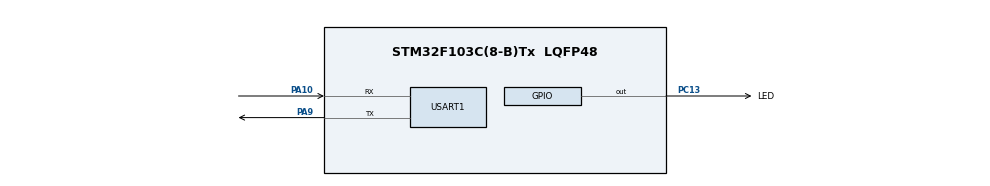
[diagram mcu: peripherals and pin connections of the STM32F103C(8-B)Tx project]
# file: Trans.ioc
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Dma.Request0=USART1_RX
Dma.Request1=USART1_TX
Dma.USART1_RX.0.Direction=DMA_PERIPH_TO_MEMORY
Dma.USART1_RX.0.Instance=DMA1_Channel5
Dma.USART1_RX.0.MemDataAlignment=DMA_MDATAALIGN_BYTE
Dma.USART1_RX.0.MemInc=DMA_MINC_ENABLE
Dma.USART1_RX.0.Mode=DMA_NORMAL
Dma.USART1_RX.0.PeriphDataAlignment=DMA_PDATAALIGN_BYTE
Dma.USART1_RX.0.PeriphInc=DMA_PINC_DISABLE
Dma.USART1_RX.0.Priority=DMA_PRIORITY_LOW
Dma.USART1_TX.1.Direction=DMA_MEMORY_TO_PERIPH
Dma.USART1_TX.1.Instance=DMA1_Channel4
Dma.USART1_TX.1.MemDataAlignment=DMA_MDATAALIGN_BYTE
Dma.USART1_TX.1.MemInc=DMA_MINC_ENABLE
Dma.USART1_TX.1.Mode=DMA_NORMAL
Dma.USART1_TX.1.PeriphDataAlignment=DMA_PDATAALIGN_BYTE
Dma.USART1_TX.1.PeriphInc=DMA_PINC_DISABLE
Dma.USART1_TX.1.Priority=DMA_PRIORITY_LOW
Mcu.Family=STM32F1
Mcu.Name=STM32F103C(8-B)Tx
Mcu.Package=LQFP48
NVIC.DMA1_Channel4_IRQn=true\:0\:0\:false\:false\:true\:false\:true\:true
NVIC.DMA1_Channel5_IRQn=true\:0\:0\:false\:false\:true\:false\:true\:true
NVIC.PriorityGroup=NVIC_PRIORITYGROUP_4
NVIC.TIM1_BRK_IRQn=true\:0\:0\:false\:false\:true\:true\:true\:true
NVIC.TIM1_CC_IRQn=true\:0\:0\:false\:false\:true\:true\:true\:true
NVIC.TIM1_TRG_COM_IRQn=true\:0\:0\:false\:false\:true\:true\:true\:true
NVIC.TIM1_UP_IRQn=true\:0\:0\:false\:false\:true\:true\:true\:true
NVIC.USART1_IRQn=true\:0\:0\:false\:false\:true\:true\:true\:true
PA10.Mode=Asynchronous
PA10.Signal=USART1_RX
PA13.Mode=Serial_Wire
PA13.Signal=SYS_JTMS-SWDIO
PA14.Mode=Serial_Wire
PA14.Signal=SYS_JTCK-SWCLK
PA9.Mode=Asynchronous
PA9.Signal=USART1_TX
PC13-TAMPER-RTC.GPIO_Label=LED
PC13-TAMPER-RTC.Signal=GPIO_Output
PD0-OSC_IN.Mode=HSE-External-Oscillator
PD0-OSC_IN.Signal=RCC_OSC_IN
PD1-OSC_OUT.Mode=HSE-External-Oscillator
PD1-OSC_OUT.Signal=RCC_OSC_OUT
ProjectManager.HeapSize=0x200
ProjectManager.StackSize=0x400
ProjectManager.TargetToolchain=STM32CubeIDE
RCC.APB1Freq_Value=8000000
RCC.APB2Freq_Value=8000000
TIM1.Period=999
TIM1.Prescaler=71
USART1.VirtualMode=VM_ASYNC
VP_TIM1_VS_ClockSourceINT.Mode=Internal
board=custom

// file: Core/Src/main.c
/* USER CODE BEGIN Header */
/**
  ******************************************************************************
  * @file           : main.c
  * @brief          : Main program body
  ******************************************************************************
  * @attention
  *
  * Copyright (c) 2024 STMicroelectronics.
  * All rights reserved.
  *
  * This software is licensed under terms that can be found in the LICENSE file
  * in the root directory of this software component.
  * If no LICENSE file comes with this software, it is provided AS-IS.
  *
  ******************************************************************************
  */
/* USER CODE END Header */
#include "main.h"

/* USER CODE BEGIN Includes */
#include <string.h>
#include <stdio.h>
char data[15] = {'A', 'B', 'C'};
char strX[10], strY[10],strZ[10];
int counter = 0, timer = 0, x = 1, y = 2, z = 3;

/* USER CODE END Includes */

TIM_HandleTypeDef htim1;

UART_HandleTypeDef huart1;
DMA_HandleTypeDef hdma_usart1_rx;
DMA_HandleTypeDef hdma_usart1_tx;

void SystemClock_Config(void);
static void MX_GPIO_Init(void);
static void MX_DMA_Init(void);
static void MX_TIM1_Init(void);
static void MX_USART1_UART_Init(void);

int main(void)
{

  /* MCU Configuration--------------------------------------------------------*/

  /* Reset of all peripherals, Initializes the Flash interface and the Systick. */
  HAL_Init();

  /* Configure the system clock */
  SystemClock_Config();

  /* Initialize all configured peripherals */
  MX_GPIO_Init();
  MX_DMA_Init();
  MX_TIM1_Init();
  MX_USART1_UART_Init();
  /* USER CODE BEGIN 2 */
  HAL_TIM_Base_Start_IT(&htim1);
  /* USER CODE END 2 */

  /* Infinite loop */
  while (1)
  {

  }
}

void SystemClock_Config(void)
{
  RCC_OscInitTypeDef RCC_OscInitStruct = {0};
  RCC_ClkInitTypeDef RCC_ClkInitStruct = {0};

  /** Initializes the RCC Oscillators according to the specified parameters
  * in the RCC_OscInitTypeDef structure.
  */
  RCC_OscInitStruct.OscillatorType = RCC_OSCILLATORTYPE_HSI;
  RCC_OscInitStruct.HSIState = RCC_HSI_ON;
  RCC_OscInitStruct.HSICalibrationValue = RCC_HSICALIBRATION_DEFAULT;
  RCC_OscInitStruct.PLL.PLLState = RCC_PLL_NONE;
  if (HAL_RCC_OscConfig(&RCC_OscInitStruct) != HAL_OK)
  {
    Error_Handler();
  }

  /** Initializes the CPU, AHB and APB buses clocks
  */
  RCC_ClkInitStruct.ClockType = RCC_CLOCKTYPE_HCLK|RCC_CLOCKTYPE_SYSCLK
                              |RCC_CLOCKTYPE_PCLK1|RCC_CLOCKTYPE_PCLK2;
  RCC_ClkInitStruct.SYSCLKSource = RCC_SYSCLKSOURCE_HSI;
  RCC_ClkInitStruct.AHBCLKDivider = RCC_SYSCLK_DIV1;
  RCC_ClkInitStruct.APB1CLKDivider = RCC_HCLK_DIV1;
  RCC_ClkInitStruct.APB2CLKDivider = RCC_HCLK_DIV1;

  if (HAL_RCC_ClockConfig(&RCC_ClkInitStruct, FLASH_LATENCY_0) != HAL_OK)
  {
    Error_Handler();
  }
}

static void MX_TIM1_Init(void)
{

  TIM_ClockConfigTypeDef sClockSourceConfig = {0};
  TIM_MasterConfigTypeDef sMasterConfig = {0};

  htim1.Instance = TIM1;
  htim1.Init.Prescaler = 71;
  htim1.Init.CounterMode = TIM_COUNTERMODE_UP;
  htim1.Init.Period = 999;
  htim1.Init.ClockDivision = TIM_CLOCKDIVISION_DIV1;
  htim1.Init.RepetitionCounter = 0;
  htim1.Init.AutoReloadPreload = TIM_AUTORELOAD_PRELOAD_DISABLE;
  if (HAL_TIM_Base_Init(&htim1) != HAL_OK)
  {
    Error_Handler();
  }
  sClockSourceConfig.ClockSource = TIM_CLOCKSOURCE_INTERNAL;
  if (HAL_TIM_ConfigClockSource(&htim1, &sClockSourceConfig) != HAL_OK)
  {
    Error_Handler();
  }
  sMasterConfig.MasterOutputTrigger = TIM_TRGO_RESET;
  sMasterConfig.MasterSlaveMode = TIM_MASTERSLAVEMODE_DISABLE;
  if (HAL_TIMEx_MasterConfigSynchronization(&htim1, &sMasterConfig) != HAL_OK)
  {
    Error_Handler();
  }

}

static void MX_USART1_UART_Init(void)
{

  huart1.Instance = USART1;
  huart1.Init.BaudRate = 115200;
  huart1.Init.WordLength = UART_WORDLENGTH_8B;
  huart1.Init.StopBits = UART_STOPBITS_1;
  huart1.Init.Parity = UART_PARITY_NONE;
  huart1.Init.Mode = UART_MODE_TX_RX;
  huart1.Init.HwFlowCtl = UART_HWCONTROL_NONE;
  huart1.Init.OverSampling = UART_OVERSAMPLING_16;
  if (HAL_UART_Init(&huart1) != HAL_OK)
  {
    Error_Handler();
  }

}

static void MX_DMA_Init(void)
{

  /* DMA controller clock enable */
  __HAL_RCC_DMA1_CLK_ENABLE();

  /* DMA interrupt init */
  /* DMA1_Channel4_IRQn interrupt configuration */
  HAL_NVIC_SetPriority(DMA1_Channel4_IRQn, 0, 0);
  HAL_NVIC_EnableIRQ(DMA1_Channel4_IRQn);
  /* DMA1_Channel5_IRQn interrupt configuration */
  HAL_NVIC_SetPriority(DMA1_Channel5_IRQn, 0, 0);
  HAL_NVIC_EnableIRQ(DMA1_Channel5_IRQn);

}

static void MX_GPIO_Init(void)
{
  GPIO_InitTypeDef GPIO_InitStruct = {0};

  /* GPIO Ports Clock Enable */
  __HAL_RCC_GPIOC_CLK_ENABLE();
  __HAL_RCC_GPIOD_CLK_ENABLE();
  __HAL_RCC_GPIOA_CLK_ENABLE();

  /*Configure GPIO pin Output Level */
  HAL_GPIO_WritePin(LED_GPIO_Port, LED_Pin, GPIO_PIN_RESET);

  /*Configure GPIO pin : LED_Pin */
  GPIO_InitStruct.Pin = LED_Pin;
  GPIO_InitStruct.Mode = GPIO_MODE_OUTPUT_PP;
  GPIO_InitStruct.Pull = GPIO_NOPULL;
  GPIO_InitStruct.Speed = GPIO_SPEED_FREQ_LOW;
  HAL_GPIO_Init(LED_GPIO_Port, &GPIO_InitStruct);

}

/* USER CODE BEGIN 4 */
void HAL_TIM_PeriodElapsedCallback(TIM_HandleTypeDef *htim){
	if(htim == &htim1){
		timer++;
		if(timer == 200){
			timer = 0;
			HAL_GPIO_WritePin(LED_GPIO_Port, LED_Pin, (counter % 2));
			x++;
			y++;
			z++;
			sprintf(strX, "%d", x);
			sprintf(strY, "%d", y);
			sprintf(strZ, "%d", z);
			memcpy(&data[3], &x , sizeof(int));
			memcpy(&data[4], &y , sizeof(int));
			memcpy(&data[5], &z , sizeof(int));

			HAL_UART_Transmit_DMA(&huart1,(uint8_t*)data, sizeof(data));
		}

//		HAL_UART_Transmit(&huart1, "aaaa", 5, 1000);
	}
}
/* USER CODE END 4 */

void Error_Handler(void)
{
  __disable_irq();
  while (1)
  {
  }
}
